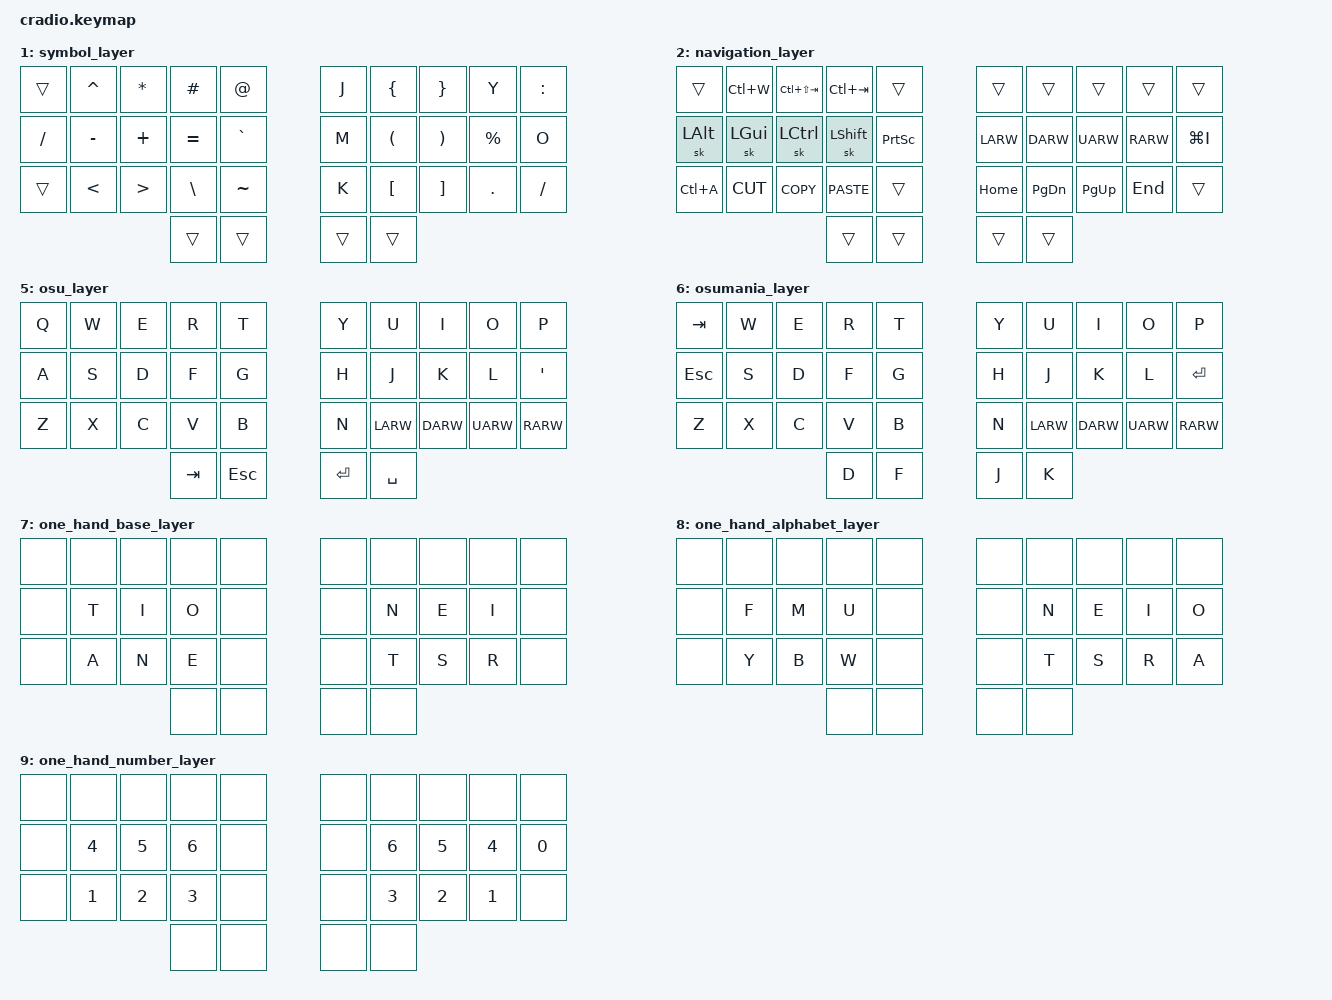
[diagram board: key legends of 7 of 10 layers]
// Copyright (c) 2022 The ZMK Contributors
// SPDX-License-Identifier: MIT

#include <behaviors.dtsi>
#include <dt-bindings/zmk/keys.h>
#include <dt-bindings/zmk/bt.h>
#include <dt-bindings/zmk/outputs.h>
#include <dt-bindings/zmk/mouse.h>

// Layer name
#define DEF 0
#define SYM 1
#define NAV 2
#define NUM 3
#define FUN 4
#define OSU 5
#define OMN 6

#define OBS 7
#define OAP 8
#define ONU 9

#define COMBO_TIME 45
#define COMBO_TIME_VERTICAL 70
#define COMBO_TIME_ONEHAND 180

// Home row mods macro
#define LHRM(k1,k2,k3,k4) &mt LALT  k1  &mt LGUI  k2  &mt LCTRL k3  &mt LSHFT k4
#define RHRM(k1,k2,k3,k4) &mt RSHFT k1  &mt RCTRL k2  &mt RGUI  k3  &mt RALT  k4

// Bluetooth shorthand for alignments
#define BTSEL(index) &bt BT_SEL index
#define BTCLR        &bt BT_CLR
#define OUTUSB       &out OUT_USB
#define OUTBLE       &out OUT_BLE

// Combo macro for shorthand
#define COMBO(name, keycode, pos, layer, time) name { \
        bindings = <keycode>; \
        key-positions = <pos>; \
        layers = <layer>; \
        timeout-ms = <time>; \
    };

// Pair hold tap behavior macro for shorthand
#define PAIR_HT(name, label_name, macros_name) name: name { \
            compatible = "zmk,behavior-hold-tap"; \
            label = label_name; \
            #binding-cells = <2>; \
            flavor = "tap-preferred"; \
            tapping-term-ms = <200>; \
            bindings = <&macros_name>, <&kp>; \
        };

&lt {
    //flavor = "tap-preferred";
    flavor = "balanced";
    tapping-term-ms = <200>;
};

&mt {
    flavor = "tap-preferred";
    tapping-term-ms = <200>;
};

&caps_word {
    continue-list = <UNDERSCORE MINUS BACKSPACE>;
};

/ {
    behaviors {
        ht: hold_tap {
            label = "hold_tap";
            compatible = "zmk,behavior-hold-tap";
            #binding-cells = <2>;
            flavor = "tap-preferred";
            tapping-term-ms = <170>;
            bindings = <&kp>, <&kp>;
        };

        mo_sl: behavior_mo_sl {
            compatible = "zmk,behavior-hold-tap";
            label = "mo_sl";
            #binding-cells = <2>;
            // flavor = "hold-preferred";
            flavor = "tap-preferred";
            tapping-term-ms = <200>;
            bindings = <&mo>, <&sl>;
        };

        mo_to: behavior_mo_to {
            compatible = "zmk,behavior-hold-tap";
            label = "mo_to";
            #binding-cells = <2>;
            // flavor = "hold-preferred";
            flavor = "tap-preferred";
            tapping-term-ms = <200>;
            bindings = <&mo>, <&to>;
        };

        mo_num: behavior_mo_num {
            compatible = "zmk,behavior-hold-tap";
            label = "mo_num";
            #binding-cells = <2>;
            // flavor = "hold-preferred";
            flavor = "tap-preferred";
            tapping-term-ms = <200>;
            bindings = <&mo>, <&num_word>;
        };

        num_word: behavior_num_word {
            compatible = "zmk,behavior-caps-word";
            label = "NUM_WORD";
            #binding-cells = <0>;
            layers = <NUM>;                                // insert location of numbers layer here
            continue-list = <BACKSPACE DELETE DOT COMMA>;  // adjust as desired
            ignore-numbers;                                // numbers don't deactivate the layer
        };

        PAIR_HT(par_ht, "par_ht", par_pair)
        PAIR_HT(brc_ht, "brc_ht", brc_pair)
        PAIR_HT(bkt_ht, "bkt_ht", bkt_pair)
        PAIR_HT(lgt_ht, "lgt_ht", lgt_pair)
        PAIR_HT(sqt_ht, "sqt_ht", sqt_pair)
        PAIR_HT(dqt_ht, "dqt_ht", dqt_pair)

    };

    macros {
        ZMK_MACRO(par_pair, wait-ms = <0>; tap-ms = <0>; bindings = <&kp LPAR &kp RPAR>;)
        ZMK_MACRO(brc_pair, wait-ms = <0>; tap-ms = <0>; bindings = <&kp LBRC &kp RBRC>;)
        ZMK_MACRO(bkt_pair, wait-ms = <0>; tap-ms = <0>; bindings = <&kp LBKT &kp RBKT>;)
        ZMK_MACRO(lgt_pair, wait-ms = <0>; tap-ms = <0>; bindings = <&kp LT   &kp GT  >;)
        ZMK_MACRO(sqt_pair, wait-ms = <0>; tap-ms = <0>; bindings = <&kp SQT  &kp SQT >;)
        ZMK_MACRO(dqt_pair, wait-ms = <0>; tap-ms = <0>; bindings = <&kp DQT  &kp DQT >;)
    };

    combos {
        compatible = "zmk,combos";

        COMBO(osu2defualt,    &to DEF,               0 1 2 3,      OSU OMN,          COMBO_TIME)
        COMBO(osu2mania,      &tog OMN,              6 7 8 9,      OSU OMN,          COMBO_TIME)

        COMBO(l_to_def,       &to DEF,               0 1 2 3,      OBS,              COMBO_TIME)
        COMBO(r_to_def,       &to DEF,               6 7 8 9,      OBS,              COMBO_TIME)
        COMBO(l_to_one,       &to OBS,               0 1 2 3,      DEF,              COMBO_TIME)
        COMBO(r_to_one,       &to OBS,               6 7 8 9,      DEF,              COMBO_TIME)

        // Top row combos
        COMBO(kpq,            &kp Q,                 1  2,      DEF NUM,  COMBO_TIME)
        COMBO(tab,            &kp TAB,                  2  3,   DEF NUM,  COMBO_TIME)
        COMBO(at_sign,        &kp AT_SIGN,           1     3,   DEF NUM,  COMBO_TIME)
        COMBO(hash,           &kp HASH,              1  2  3,   DEF NUM,  COMBO_TIME)

        COMBO(semicolon,      &kp SEMICOLON,         6  7,      DEF NUM,  COMBO_TIME)
        COMBO(colon,          &kp COLON,                7  8,   DEF NUM,  COMBO_TIME)
        // COMBO(caret,          &kp CARET,             6     8,   DEF NUM,  COMBO_TIME)
        // COMBO(mouse_layer,    &tog MOU,              6  7  8,   DEF MOU,  COMBO_TIME)
        COMBO(equal,          &kp EQUAL,             6  7  8,   DEF NUM,  COMBO_TIME)

        // Home row combos
        COMBO(escape,         &kp ESCAPE,               12 13,  DEF NUM,  COMBO_TIME)
        COMBO(sqt,            &kp SQT,               11 12,     DEF NUM,  COMBO_TIME)
        COMBO(caps_word,      &caps_word,            11    13,  DEF NUM,  COMBO_TIME)
        COMBO(repeat,         &key_repeat,           11 12 13,  DEF NUM,  COMBO_TIME)

        COMBO(backspace,      &kp BACKSPACE,         16 17,     DEF NUM,  COMBO_TIME)
        COMBO(dqt,            &kp DQT,                  17 18,  DEF NUM,  COMBO_TIME)
        COMBO(enter,          &kp ENTER,             16 17 18,  DEF NUM,  COMBO_TIME)
        COMBO(delete,         &kp DELETE,            15 16,     DEF NUM,  COMBO_TIME)

        // Bottom row combos
        COMBO(kpz,            &kp Z,                    22 23,  DEF NUM,  COMBO_TIME)
        // COMBO(dqt,            &kp DQT,               21 22,     DEF NUM,  COMBO_TIME)
        COMBO(question,       &kp QUESTION,          21    23,  DEF NUM,  COMBO_TIME)
        COMBO(exclamation,    &kp EXCLAMATION,       21 22 23,  DEF NUM,  COMBO_TIME)

        COMBO(dollar,         &kp DOLLAR,            26 27,     DEF NUM,  COMBO_TIME)
        // COMBO(sqt,            &kp SQT,                  27 28,  DEF NUM,  COMBO_TIME)
        COMBO(ampersand,      &kp AMPERSAND,         26    28,  DEF NUM,  COMBO_TIME)
        COMBO(pipe,           &kp PIPE,              26 27 28,  DEF NUM,  COMBO_TIME)

        // COMBO(b_ackspace,     &kp BACKSPACE,         12 23,     DEF NUM,  COMBO_TIME)

        // COMBO(l_shift,        &sk LSHFT,             11 12,     DEF NUM,  COMBO_TIME)
        // COMBO(l_ctrl,         &sk LCTRL,                12 23,  DEF NUM,  COMBO_TIME)
        // COMBO(l_gui,          &sk LGUI,              11 12 23,  DEF NUM,  COMBO_TIME)
        // COMBO(l_alt,          &sk LALT,              11    23,  DEF NUM,  COMBO_TIME)
        // COMBO(r_shift,        &sk RSHFT,                17 18,  DEF NUM,  COMBO_TIME)
        // COMBO(r_ctrl,         &sk RCTRL,             26 17,     DEF NUM,  COMBO_TIME)
        // COMBO(r_gui,          &sk RGUI,              26 17 18,  DEF NUM,  COMBO_TIME)
        // COMBO(r_alt,          &sk RALT,              26 17,     DEF NUM,  COMBO_TIME)

        // Vertical combos
        COMBO(v_lpar,         &kp LPAR,              6  16,     DEF NUM,  COMBO_TIME_VERTICAL)
        COMBO(v_rpar,         &kp RPAR,              7  17,     DEF NUM,  COMBO_TIME_VERTICAL)
        COMBO(v_lbkt,         &kp LBKT,              16 26,     DEF NUM,  COMBO_TIME_VERTICAL)
        COMBO(v_rbkt,         &kp RBKT,              17 27,     DEF NUM,  COMBO_TIME_VERTICAL)
        COMBO(v_lbrc,         &kp LBRC,              2  12,     DEF NUM,  COMBO_TIME_VERTICAL)
        COMBO(v_rbrc,         &kp RBRC,              3  13,     DEF NUM,  COMBO_TIME_VERTICAL)
        COMBO(v_lt,           &kp LT,                12 22,     DEF NUM,  COMBO_TIME_VERTICAL)
        COMBO(v_gt,           &kp GT,                13 23,     DEF NUM,  COMBO_TIME_VERTICAL)
        COMBO(v_dqt,          &kp DQT,               10 20,     DEF NUM,  COMBO_TIME_VERTICAL)
        COMBO(v_sqt,          &kp SQT,               19 29,     DEF NUM,  COMBO_TIME_VERTICAL)



        // One hand
        COMBO(l_one_base_h,          &kp H,                       12 13,     OBS,  COMBO_TIME_ONEHAND)
        COMBO(l_one_base_l,          &kp L,                    11 12   ,     OBS,  COMBO_TIME_ONEHAND)
        COMBO(l_one_base_c,          &kp C,                    11    13,     OBS,  COMBO_TIME_ONEHAND)
        COMBO(l_one_base_sw,         &sl OAP,                  11 12 13,     OBS,  COMBO_TIME_ONEHAND)

        COMBO(l_one_base_s,          &kp S,                       22 23,     OBS,  COMBO_TIME_ONEHAND)
        COMBO(l_one_base_r,          &kp R,                    21 22   ,     OBS,  COMBO_TIME_ONEHAND)
        COMBO(l_one_base_d,          &kp D,                    21    23,     OBS,  COMBO_TIME_ONEHAND)
        COMBO(l_one_base_sp,         &kp SPACE,                21 22 23,     OBS,  COMBO_TIME_ONEHAND)

        COMBO(l_one_base_backspace,  &kp BACKSPACE,               12 23,     OBS,  COMBO_TIME_ONEHAND)
        COMBO(l_one_base_alt,        &sk LALT,                 11 22   ,     OBS,  COMBO_TIME_ONEHAND)
        COMBO(l_one_base_ctrl,       &sk LCTRL,                11    23,     OBS,  COMBO_TIME_ONEHAND)
        COMBO(l_one_base_shift,      &sk LSHFT,                11 12 23,     OBS,  COMBO_TIME_ONEHAND)
        COMBO(l_one_base_gui,        &sk LGUI,                 11 22 23,     OBS,  COMBO_TIME_ONEHAND)

        COMBO(l_one_base_comma,      &kp COMMA,                   22 13,     OBS,  COMBO_TIME_ONEHAND)
        COMBO(l_one_base_sqt,        &kp SQT,                  21 12   ,     OBS,  COMBO_TIME_ONEHAND)
        COMBO(l_one_base_dot,        &kp DOT,                  21    13,     OBS,  COMBO_TIME_ONEHAND)
        COMBO(l_one_base_esc,        &kp ESC,                  21 12 13,     OBS,  COMBO_TIME_ONEHAND)
        COMBO(l_one_base_tab,        &kp TAB,                  21 22 13,     OBS,  COMBO_TIME_ONEHAND)

        // COMBO(l_one_base_,           &kp,                      11 22 13,     OBS,  COMBO_TIME_ONEHAND)
        // COMBO(l_one_base_,           &kp,                      11 11   ,     OBS,  COMBO_TIME_ONEHAND)
        COMBO(l_one_base_repeat,     &key_repeat,              12 22   ,     OBS,  COMBO_TIME_ONEHAND)
        // COMBO(l_one_base_,           &kp,                      11 21 12 22,  OBS,  COMBO_TIME_ONEHAND)

        // COMBO(l_one_base_,           &kp,                      21 12 23,     OBS,  COMBO_TIME_ONEHAND)
        COMBO(l_one_base_enter,      &kp ENTER,                13 23   ,     OBS,  COMBO_TIME_ONEHAND)
        // COMBO(l_one_base_,           &kp,                      11 21 13 23,  OBS,  COMBO_TIME_ONEHAND)
        COMBO(l_one_base_cap_word,   &caps_word,               12 22 13 23,  OBS,  COMBO_TIME_ONEHAND)


        COMBO(l_one_alhp_g,          &kp G,                       12 13,     OAP,  COMBO_TIME_ONEHAND)
        COMBO(l_one_alhp_p,          &kp P,                    11 12   ,     OAP,  COMBO_TIME_ONEHAND)
        COMBO(l_one_alhp_v,          &kp V,                    11    13,     OAP,  COMBO_TIME_ONEHAND)
        COMBO(l_one_alhp_under,      &kp UNDER,                11 12 13,     OAP,  COMBO_TIME_ONEHAND)

        COMBO(l_one_alhp_k,          &kp K,                       22 23,     OAP,  COMBO_TIME_ONEHAND)
        COMBO(l_one_alhp_j,          &kp J,                    21 22   ,     OAP,  COMBO_TIME_ONEHAND)
        COMBO(l_one_alhp_x,          &kp X,                    21    23,     OAP,  COMBO_TIME_ONEHAND)
        COMBO(l_one_alhp_q,          &kp Q,                    21 22 23,     OAP,  COMBO_TIME_ONEHAND)

        COMBO(l_one_alhp_z,          &kp Z,                       12 23,     OAP,  COMBO_TIME_ONEHAND)
        // COMBO(l_one_alhp_alt,        &sk LALT,                 11 22   ,     OAP,  COMBO_TIME_ONEHAND)
        // COMBO(l_one_alhp_ctrl,       &sk LCTRL,                11    23,     OAP,  COMBO_TIME_ONEHAND)
        // COMBO(l_one_alhp_shift,      &sk LSHFT,                11 12 23,     OAP,  COMBO_TIME_ONEHAND)
        // COMBO(l_one_alhp_gui,        &sk LGUI,                 11 22 23,     OAP,  COMBO_TIME_ONEHAND)

        // COMBO(l_one_alhp_comma,      &kp COMMA,                   22 13,     OAP,  COMBO_TIME_ONEHAND)
        // COMBO(l_one_alhp_sqt,        &kp SQT,                  21 12   ,     OAP,  COMBO_TIME_ONEHAND)
        // COMBO(l_one_alhp_dot,        &kp DOT,                  21    13,     OAP,  COMBO_TIME_ONEHAND)
        // COMBO(l_one_alhp_esc,        &kp ESC,                  21 12 13,     OAP,  COMBO_TIME_ONEHAND)
        // COMBO(l_one_alhp_tab,        &kp TAB,                  21 22 13,     OAP,  COMBO_TIME_ONEHAND)

        // COMBO(l_one_alhp_,           &kp,                      11 22 13,     OAP,  COMBO_TIME_ONEHAND)
        // COMBO(l_one_alhp_,           &kp,                      11 11   ,     OAP,  COMBO_TIME_ONEHAND)
        // COMBO(l_one_alhp_,           &kp,                      12 22   ,     OAP,  COMBO_TIME_ONEHAND)
        // COMBO(l_one_alhp_,           &kp,                      11 21 12 22,  OAP,  COMBO_TIME_ONEHAND)

        // COMBO(l_one_alhp_,           &kp,                      21 12 23,     OAP,  COMBO_TIME_ONEHAND)
        // COMBO(l_one_alhp_,           &kp,                      13 13   ,     OAP,  COMBO_TIME_ONEHAND)
        // COMBO(l_one_alhp_,           &kp,                      11 21 13 23,  OAP,  COMBO_TIME_ONEHAND)
        COMBO(l_one_alhp_cap_lock,   &kp CAPSLOCK,             12 22 13 23,  OAP,  COMBO_TIME_ONEHAND)
    };

    conditional_layers {
        compatible = "zmk,conditional-layers";
        number_layer {
            if-layers = <SYM NAV>;
            then-layer = <NUM>;
        };
    };

    keymap {
        compatible = "zmk,keymap";
        default_layer {
            bindings = <
            &kp Q      &kp W      &kp F      &kp P      &kp B          &kp J      &kp L      &kp U      &kp Y      &kp COLON
            LHRM(A,        R,         S,         T)     &kp G          &kp M      RHRM(N,        E,         I,         O)
            &kp UNDER  &kp X      &kp C      &kp D      &kp V          &kp K      &kp H      &kp COMMA  &kp DOT    &kp FSLH
            // &kp A      &kp R      &kp S      &kp T      &kp G          &kp M      &kp N      &kp E      &kp I      &kp O
                                      &sl NAV  &lt NAV SPACE       &lt SYM ENTER    &sl NUM
            >;
        };

        symbol_layer {
            bindings = <
            &trans     &kp CARET  &kp ASTRK  &kp HASH   &kp AT         &kp J      &kp LBRC   &kp RBRC   &kp Y      &kp COLON
            &kp FSLH   &kp MINUS  &kp PLUS   &kp EQUAL  &kp GRAVE      &kp M      &kp LPAR   &kp RPAR   &kp PRCNT  &kp O
            &trans     &kp LT     &kp GT     &kp BSLH   &kp TILDE      &kp K      &kp LBKT   &kp RBKT   &kp DOT    &kp FSLH
                                             &trans     &trans         &trans     &trans
            >;
        };

        navigation_layer {
            bindings = <
            &trans     &kp LC(W)  &kp LC(LS(TAB)) &kp LC(TAB) &trans        &trans     &trans     &trans     &trans     &trans
            &sk LALT   &sk LGUI   &sk LCTRL  &sk LSHFT  &kp PSCRN       &kp LARW   &kp DARW   &kp UARW   &kp RARW   &kp LG(I)
            &kp LC(A)  &kp K_CUT  &kp K_COPY &kp K_PASTE &trans         &kp HOME   &kp PG_DN  &kp PG_UP  &kp END    &trans
                                             &trans     &trans         &trans     &trans
            >;
        };

        number_layer {
            bindings = <
            &trans     &kp MINUS  &kp PLUS   &kp EQUAL  &kp TILDE      &trans     &kp DARW   &kp UARW   &kp AT    &trans
            LHRM(N7,       N8,        N9,        N0)    &kp GRAVE      &trans     RHRM(N1,       N2,        N3,        N4)
            &kp PRCNT  &kp CARET  &kp ASTRK  &kp N6     &kp BSLH       &trans     &kp N5     &kp COMMA  &kp DOT   &kp FSLH
                                             &trans     &trans         &trans     &sl FUN
            >;
        };

        function_layer {
            bindings = <
            &trans     &trans     OUTBLE     OUTUSB     BTCLR          BTSEL(0)   BTSEL(1)   BTSEL(2)   BTSEL(3)   BTSEL(4)
            LHRM(F7,       F8,        F9,        F10)   &kp F12        &kp F11    RHRM(F1,       F2,        F3,        F4)
            &to OSU    &trans     &trans     &kp F6     &trans         &trans     &kp F5     &trans     &trans     &trans
                                             &trans     &trans         &trans     &trans
            >;
        };

        osu_layer {
            bindings = <
            &kp Q      &kp W      &kp E      &kp R      &kp T          &kp Y      &kp U      &kp I      &kp O      &kp P
            &kp A      &kp S      &kp D      &kp F      &kp G          &kp H      &kp J      &kp K      &kp L      &kp SQT
            &kp Z      &kp X      &kp C      &kp V      &kp B          &kp N      &kp LARW   &kp DARW   &kp UARW   &kp RARW
                                             &kp TAB    &kp ESC        &kp ENTER  &kp SPACE
            >;
        };

        osumania_layer {
            bindings = <
            &kp TAB    &kp W      &kp E      &kp R      &kp T          &kp Y      &kp U      &kp I      &kp O      &kp P
            &kp ESC    &kp S      &kp D      &kp F      &kp G          &kp H      &kp J      &kp K      &kp L      &kp ENTER
            &kp Z      &kp X      &kp C      &kp V      &kp B          &kp N      &kp LARW   &kp DARW   &kp UARW   &kp RARW
                                             &kp D      &kp F          &kp J      &kp K
            >;
        };



        one_hand_base_layer {
            bindings = <
            &none      &none      &none      &none      &none          &none      &none      &none      &none      &none
            &none      &kp T      &kp I      &kp O      &none          &none      &kp N      &kp E      &kp I      &none
            &none      &kp A      &kp N      &kp E      &none          &none      &kp T      &kp S      &kp R      &none
                                             &none      &none          &none      &none
            >;
        };

        one_hand_alphabet_layer {
            bindings = <
            &none      &none      &none      &none      &none          &none      &none      &none      &none      &none
            &none      &kp F      &kp M      &kp U      &none          &none      &kp N      &kp E      &kp I      &kp O
            &none      &kp Y      &kp B      &kp W      &none          &none      &kp T      &kp S      &kp R      &kp A
                                             &none      &none          &none      &none
            >;
        };

        one_hand_number_layer {
            bindings = <
            &none      &none      &none      &none      &none          &none      &none      &none      &none      &none
            &none      &kp N4     &kp N5     &kp N6     &none          &none      &kp N6     &kp N5     &kp N4     &kp N0
            &none      &kp N1     &kp N2     &kp N3     &none          &none      &kp N3     &kp N2     &kp N1     &none
                                             &none      &none          &none      &none
            >;
        };
    };
};
